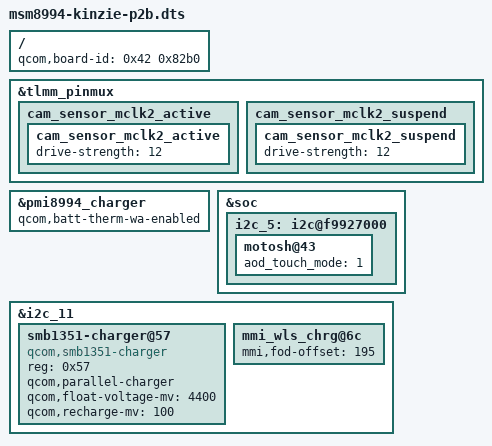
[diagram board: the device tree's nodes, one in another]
/* Copyright (c) 2015, Motorla Mobility LLC. All rights reserved.
 *
 * This program is free software; you can redistribute it and/or modify
 * it under the terms of the GNU General Public License version 2 and
 * only version 2 as published by the Free Software Foundation.
 *
 * This program is distributed in the hope that it will be useful,
 * but WITHOUT ANY WARRANTY; without even the implied warranty of
 * MERCHANTABILITY or FITNESS FOR A PARTICULAR PURPOSE.  See the
 * GNU General Public License for more details.
 */


/dts-v1/;

#include "msm8994-kinzie-v2.1.dtsi"

/ {
	qcom,board-id = <0x42 0x82b0>;
};

&tlmm_pinmux {
	cam_sensor_mclk2_active {
		/* active state */
		cam_sensor_mclk2_active: cam_sensor_mclk2_active {
			drive-strength = <12>; /* 12 MA */
		};
	};

	cam_sensor_mclk2_suspend {
		/* suspend state */
		cam_sensor_mclk2_suspend: cam_sensor_mclk2_suspend {
			drive-strength = <12>; /* 12 MA */
		};
	};
};

&pmi8994_charger {
	qcom,batt-therm-wa-enabled;
};

&soc {
	i2c_5: i2c@f9927000 {
		motosh@43 {
			aod_touch_mode = <1>;
		};
	};
};

&i2c_11 {
	smb1351-charger@57 {
		status = "ok";
		compatible = "qcom,smb1351-charger";
		reg = <0x57>;
		qcom,parallel-charger;
		qcom,float-voltage-mv = <4400>;
		qcom,recharge-mv = <100>;
	};

	mmi_wls_chrg@6c {
		mmi,fod-offset = <195>;
	};
};
